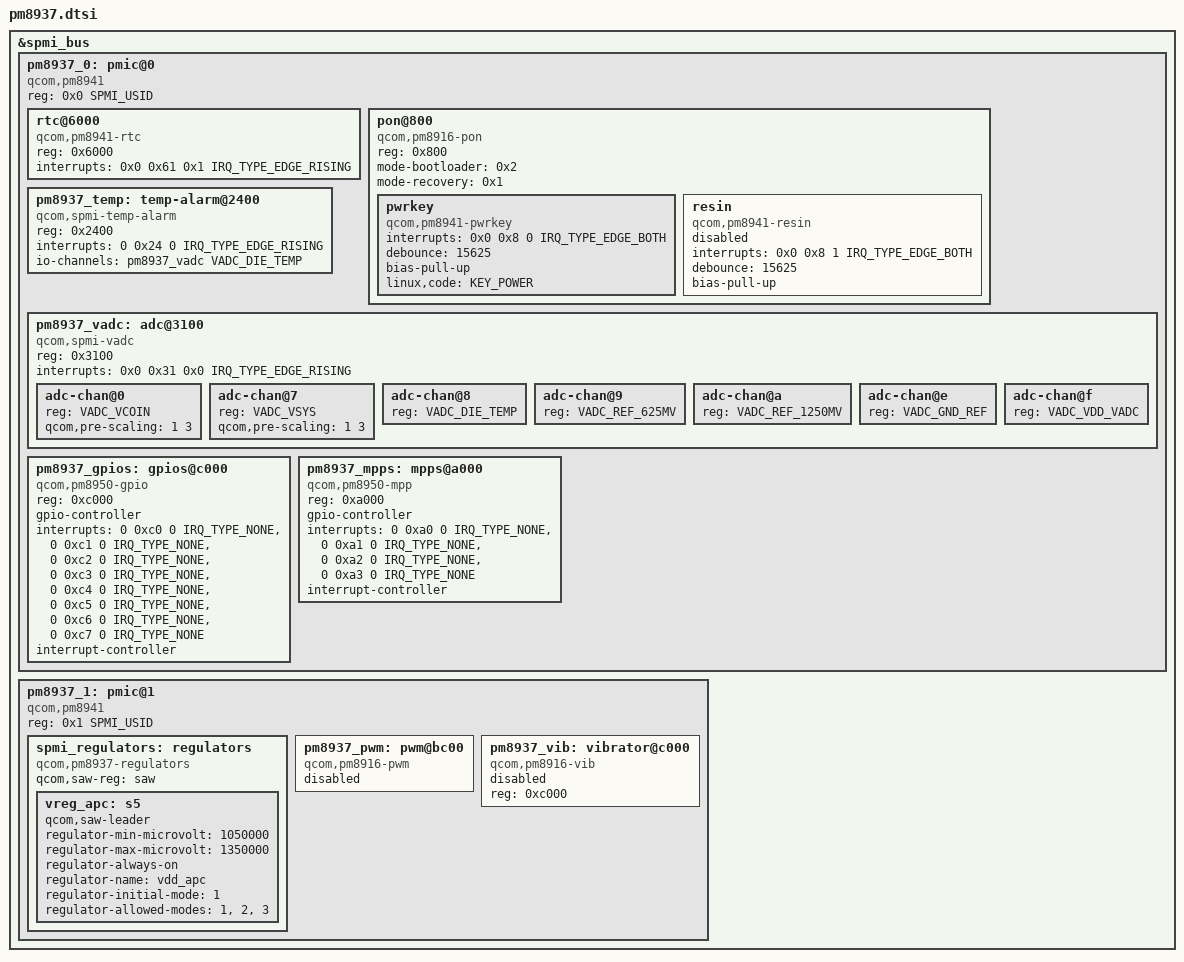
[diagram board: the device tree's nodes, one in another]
// SPDX-License-Identifier: GPL-2.0
#include <dt-bindings/iio/qcom,spmi-vadc.h>
#include <dt-bindings/input/linux-event-codes.h>
#include <dt-bindings/interrupt-controller/irq.h>
#include <dt-bindings/spmi/spmi.h>

&spmi_bus {
	pm8937_0: pmic@0 {
		compatible = "qcom,pm8941", "qcom,spmi-pmic";
		reg = <0x0 SPMI_USID>;
		#address-cells = <1>;
		#size-cells = <0>;

		rtc@6000 {
			compatible = "qcom,pm8941-rtc";
			reg = <0x6000>;
			reg-names = "rtc", "alarm";
			interrupts = <0x0 0x61 0x1 IRQ_TYPE_EDGE_RISING>;
		};

		pon@800 {
			compatible = "qcom,pm8916-pon";
			reg = <0x800>;
			mode-bootloader = <0x2>;
			mode-recovery = <0x1>;

			pwrkey {
				compatible = "qcom,pm8941-pwrkey";
				interrupts = <0x0 0x8 0 IRQ_TYPE_EDGE_BOTH>;
				debounce = <15625>;
				bias-pull-up;
				linux,code = <KEY_POWER>;
			};

			resin {
				compatible = "qcom,pm8941-resin";
				interrupts = <0x0 0x8 1 IRQ_TYPE_EDGE_BOTH>;
				debounce = <15625>;
				bias-pull-up;
				status = "disabled";
			};
		};

		pm8937_temp: temp-alarm@2400 {
			compatible = "qcom,spmi-temp-alarm";
			reg = <0x2400>;
			interrupts = <0 0x24 0 IRQ_TYPE_EDGE_RISING>;
			io-channels = <&pm8937_vadc VADC_DIE_TEMP>;
			io-channel-names = "thermal";
			#thermal-sensor-cells = <0>;
		};

		pm8937_vadc: adc@3100 {
			compatible = "qcom,spmi-vadc";
			reg = <0x3100>;
			interrupts = <0x0 0x31 0x0 IRQ_TYPE_EDGE_RISING>;
			#address-cells = <1>;
			#size-cells = <0>;
			#io-channel-cells = <1>;

			adc-chan@0 {
				reg = <VADC_VCOIN>;
				qcom,pre-scaling = <1 3>;
			};
			adc-chan@7 {
				reg = <VADC_VSYS>;
				qcom,pre-scaling = <1 3>;
			};
			adc-chan@8 {
				reg = <VADC_DIE_TEMP>;
			};
			adc-chan@9 {
				reg = <VADC_REF_625MV>;
			};
			adc-chan@a {
				reg = <VADC_REF_1250MV>;
			};
			adc-chan@e {
				reg = <VADC_GND_REF>;
			};
			adc-chan@f {
				reg = <VADC_VDD_VADC>;
			};
		};

		pm8937_gpios: gpios@c000 {
			compatible = "qcom,pm8950-gpio";
			reg = <0xc000>;
			gpio-controller;
			#gpio-cells = <2>;
			interrupts = <0 0xc0 0 IRQ_TYPE_NONE>,
				     <0 0xc1 0 IRQ_TYPE_NONE>,
				     <0 0xc2 0 IRQ_TYPE_NONE>,
				     <0 0xc3 0 IRQ_TYPE_NONE>,
				     <0 0xc4 0 IRQ_TYPE_NONE>,
				     <0 0xc5 0 IRQ_TYPE_NONE>,
				     <0 0xc6 0 IRQ_TYPE_NONE>,
				     <0 0xc7 0 IRQ_TYPE_NONE>;
			interrupt-controller;
			#interrupt-cells = <2>;
		};

		pm8937_mpps: mpps@a000 {
			compatible = "qcom,pm8950-mpp";
			reg = <0xa000>;
			gpio-controller;
			#gpio-cells = <2>;
			interrupts = <0 0xa0 0 IRQ_TYPE_NONE>,
				     <0 0xa1 0 IRQ_TYPE_NONE>,
				     <0 0xa2 0 IRQ_TYPE_NONE>,
				     <0 0xa3 0 IRQ_TYPE_NONE>;
			interrupt-controller;
			#interrupt-cells = <2>;
		};
	};

	pm8937_1: pmic@1 {
		compatible = "qcom,pm8941", "qcom,spmi-pmic";
		reg = <0x1 SPMI_USID>;
		#address-cells = <1>;
		#size-cells = <0>;
		spmi_regulators: regulators {
			compatible = "qcom,pm8937-regulators";
			qcom,saw-reg = <&saw>;
			vreg_apc: s5 {
				qcom,saw-leader;
				regulator-min-microvolt = <1050000>;
				regulator-max-microvolt = <1350000>;
				regulator-always-on;
				regulator-name = "vdd_apc";
				regulator-initial-mode = <1>;
				regulator-allowed-modes = <1>, <2>, <3>;
			};
		};

		pm8937_pwm: pwm@bc00 {
			compatible = "qcom,pm8916-pwm";
			#pwm-cells = <2>;
			status = "disabled";
		};

		pm8937_vib: vibrator@c000 {
			compatible = "qcom,pm8916-vib";
			reg = <0xc000>;
			status = "disabled";
		};
	};
};
